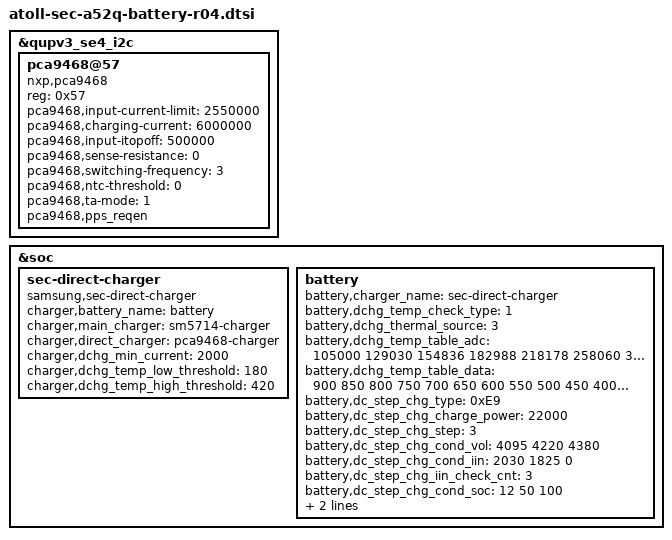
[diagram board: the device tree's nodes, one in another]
/* Copyright (c) 2016-2019, The Linux Foundation. All rights reserved.
 *
 * This program is free software; you can redistribute it and/or modify
 * it under the terms of the GNU General Public License version 2 and
 * only version 2 as published by the Free Software Foundation.
 *
 * This program is distributed in the hope that it will be useful,
 * but WITHOUT ANY WARRANTY; without even the implied warranty of
 * MERCHANTABILITY or FITNESS FOR A PARTICULAR PURPOSE.  See the
 * GNU General Public License for more details.
 */

#include <dt-bindings/iio/qcom,spmi-vadc.h>
#include "atoll-sec-a52q-battery-common.dtsi"

&qupv3_se4_i2c {
	status = "okay";

	pca9468@57 {
		compatible = "nxp,pca9468";
		reg = <0x57>;

		pinctrl-names = "default";
		pca9468,input-current-limit = <2550000>; /* 2.55A */
		pca9468,charging-current = <6000000>; /* 6A */
		pca9468,input-itopoff = <500000>; /* 500mA */
		pca9468,sense-resistance = <0>; /* 5mOhm */
		pca9468,switching-frequency = <3>; /* 980KHz */
		pca9468,ntc-threshold = <0>; /* disable */
		pca9468,ta-mode = <1>; /* 2:1 charging mode */
		pca9468,pps_reqen;
	};
};

&soc {
	sec-direct-charger {
		status = "okay";
		compatible = "samsung,sec-direct-charger";

		charger,battery_name = "battery";
		charger,main_charger = "sm5714-charger";
		charger,direct_charger = "pca9468-charger";

		charger,dchg_min_current = <2000>;
		charger,dchg_temp_low_threshold = <180>;
		charger,dchg_temp_high_threshold = <420>;

	};

	battery {
		battery,charger_name = "sec-direct-charger";

		battery,dchg_temp_check_type = <1>;
		battery,dchg_thermal_source = <3>; /* SEC_BATTERY_THERMAL_SOURCE_CHG_ADC */

		battery,dchg_temp_table_adc = <105000 129030 154836 182988 218178
						258060 304980 361284 426972 499698
						577116 668610 769488 872712 978282
						1081506 1184730 1280916 1367718 1447482
						1515516 1576512 1625778>;
		battery,dchg_temp_table_data = <900 850 800 750 700
						650 600 550 500 450
						400 350 300 250 200
						150 100 50 0 (-50)
						(-100) (-150) (-200)>;

		/* direct step charging option */
		battery,dc_step_chg_type = <0xE9>;
		battery,dc_step_chg_charge_power = <22000>;
		battery,dc_step_chg_step = <3>;
		battery,dc_step_chg_cond_vol = <4095 4220 4380>; /* STEP_CHARGING_CONDITION_VOLTAGE */
		battery,dc_step_chg_cond_iin = <2030 1825 0>; /* STEP_CHARGING_CONDITION_INPUT_CURRENT */
		battery,dc_step_chg_iin_check_cnt = <3>;
		battery,dc_step_chg_cond_soc = <12 50 100>; /* STEP_CHARGING_CONDITION_SOC */
		battery,dc_step_chg_val_vfloat = <4095 4220 4380>; /* STEP_CHARGING_CONDITION_FLOAT_VOLTAGE */
		battery,dc_step_chg_val_iout = <5000 4060 3650>;
	};
};
